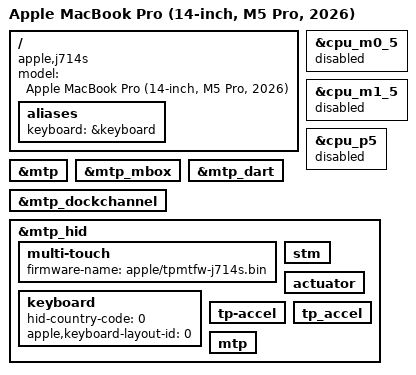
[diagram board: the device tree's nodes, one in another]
// SPDX-License-Identifier: GPL-2.0+ OR MIT
/*
 * Apple MacBook Pro (14-inch, M5 Pro, 2026)
 *
 * target-type: J714s (Mac17,9)
 *
 * Copyright The Asahi Linux Contributors / omarchy-m5 contributors
 */

/dts-v1/;

#include "t6050.dtsi"
#include "t6050-jxxx.dtsi"

/ {
	compatible = "apple,j714s", "apple,t6050", "apple,arm-platform";
	model = "Apple MacBook Pro (14-inch, M5 Pro, 2026)";

	aliases {
		/* m1n1 dt_set_ipd(): fills apple,keyboard-layout-id/hid-country-code
		 * from /arm-io/dockchannel-mtp/mtp-transport/keyboard kblang-calibration */
		keyboard = &keyboard;
	};
};

/* J714s is a binned SKU: 5 cores per cluster, cpu5/cpu11/cpu17 fused off */
&cpu_m0_5 { status = "disabled"; };
&cpu_m1_5 { status = "disabled"; };
&cpu_p5   { status = "disabled"; };

/*
 * Built-in keyboard + trackpad (MTP). The keyboard needs no firmware; the
 * trackpad (ADT multi-touch: bootloader-type CBOR, personality C1FD0,8)
 * needs apple/tpmtfw-j714s.bin extracted from the macOS restore bundle.
 */
&mtp {
	status = "okay";
};

&mtp_mbox {
	status = "okay";
};

&mtp_dart {
	status = "okay";
};

&mtp_dockchannel {
	status = "okay";
};

&mtp_hid {
	multi-touch {
		firmware-name = "apple/tpmtfw-j714s.bin";
	};

	keyboard: keyboard {
		hid-country-code = <0>;
		apple,keyboard-layout-id = <0>;
	};

	stm {
	};

	actuator {
	};

	/* ADT calls it tp-accel; the M2/M3 DTs use tp_accel. Which name the
	 * firmware announces decides which node binds; the other is inert. */
	tp-accel {
	};

	tp_accel {
	};

	/* an extra "mtp" interface exists on the M4 Air (GravityLinux PR #1) */
	mtp {
	};
};

/* SMC sensors: two fans (F0Ac/F1Ac), laptop temperature/power keys (stage-0 probe). */
#include "hwmon-common.dtsi"
#include "hwmon-fan-dual.dtsi"
#include "hwmon-laptop.dtsi"
